# ESP32 register map
Vendor: ESPRESSIF SYSTEMS (SHANGHAI) CO., LTD.; Series: ESP32 Series; File version: 17
CPU: Xtensa LX6 r0p0, little endian, no MPU, FPU, 0 interrupt priority bits
Address unit: 32 bits
Registers are 32-bit, read-write, reset 0x0 unless marked. A register's access mark holds for its fields unless they carry their own. Offsets are from the block's base; [hi:lo] are bit positions; {n}, {i} and the like mark numbered series.

## LEDC — LED Control PWM (Pulse Width Modulation)
Base 0x3FF59000
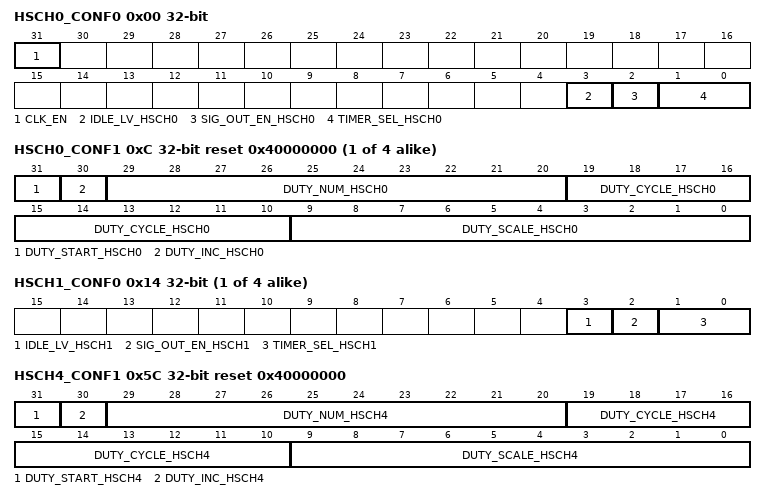
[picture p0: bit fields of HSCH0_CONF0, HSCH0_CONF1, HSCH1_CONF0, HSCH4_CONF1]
0x00 HSCH0_CONF0
  [31] CLK_EN — This bit is clock gating control signal. when software config LED_PWM internal registers it controls the register clock.
  [3] IDLE_LV_HSCH0 — This bit is used to control the output value when high speed channel0 is off.
  [2] SIG_OUT_EN_HSCH0 — This is the output enable control bit for high speed channel0
  [1:0] TIMER_SEL_HSCH0 — There are four high speed timers the two bits are used to select one of them for high speed channel0. 2'b00: seletc hstimer0. 2'b01: select hstimer1. 2'b10: select hstimer2. 2'b11: select hstimer3.
{0x4+0x14*i} HSCH{i}_HPOINT (i=0..7)
  [19:0] HPOINT_HSCH{i} — The output value changes to high when htimerx(x=[0 3]) selected by high speed channel{i} has reached reg_hpoint_hsch{i}[19:0]
{0x8+0x14*i} HSCH{i}_DUTY ro (i=0..7)
  [24:0] DUTY_HSCH{i} — This register represents the current duty of the output signal for high speed channel{i}.
{0xC+0x14*i} HSCH{i}_CONF1 reset 0x40000000 (i=0..3)
  [31] DUTY_START_HSCH{i} — When reg_duty_num_hsch{i} reg_duty_cycle_hsch{i} and reg_duty_scale_hsch{i} has been configured. these register won't take effect until set reg_duty_start_hsch{i}. this bit is automatically cleared by hardware.
  [30] DUTY_INC_HSCH{i} — This register is used to increase the duty of output signal or decrease the duty of output signal for high speed channel{i}.
  [29:20] DUTY_NUM_HSCH{i} — This register is used to control the num of increased or decreased times for high speed channel{i}.
  [19:10] DUTY_CYCLE_HSCH{i} — This register is used to increase or decrease the duty every reg_duty_cycle_hsch{i} cycles for high speed channel{i}.
  [9:0] DUTY_SCALE_HSCH{i} — This register controls the increase or decrease step scale for high speed channel{i}.
{0x10+0x14*i} HSCH{i}_DUTY_R access not given (i=0..7)
{0x0+0x14*i} HSCH{i}_CONF0 (i=1..4)
  [3] IDLE_LV_HSCH{i} — This bit is used to control the output value when high speed channel{i} is off.
  [2] SIG_OUT_EN_HSCH{i} — This is the output enable control bit for high speed channel{i}
  [1:0] TIMER_SEL_HSCH{i} — There are four high speed timers the two bits are used to select one of them for high speed channel{i}. 2'b00: seletc hstimer0. 2'b01: select hstimer1. 2'b10: select hstimer2. 2'b11: select hstimer3.
0x5C HSCH4_CONF1 reset 0x40000000
  [31] DUTY_START_HSCH4 — When reg_duty_num_hsch1 reg_duty_cycle_hsch1 and reg_duty_scale_hsch1 has been configured. these register won't take effect until set reg_duty_start_hsch1. this bit is automatically cleared by hardware.
  [30] DUTY_INC_HSCH4 — This register is used to increase the duty of output signal or decrease the duty of output signal for high speed channel4.
  [29:20] DUTY_NUM_HSCH4 — This register is used to control the num of increased or decreased times for high speed channel1.
  [19:10] DUTY_CYCLE_HSCH4 — This register is used to increase or decrease the duty every reg_duty_cycle_hsch4 cycles for high speed channel4.
  [9:0] DUTY_SCALE_HSCH4 — This register controls the increase or decrease step scale for high speed channel4.
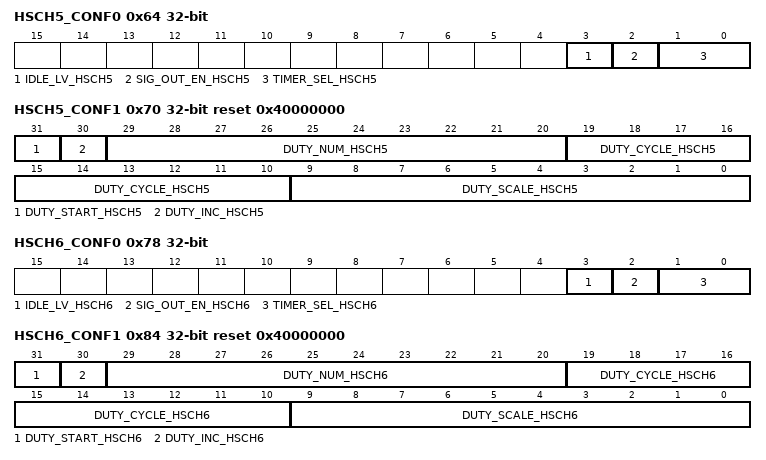
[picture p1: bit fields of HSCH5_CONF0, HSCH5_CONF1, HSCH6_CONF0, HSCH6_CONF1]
0x64 HSCH5_CONF0
  [3] IDLE_LV_HSCH5 — This bit is used to control the output value when high speed channel5 is off.
  [2] SIG_OUT_EN_HSCH5 — This is the output enable control bit for high speed channel5.
  [1:0] TIMER_SEL_HSCH5 — There are four high speed timers the two bits are used to select one of them for high speed channel5. 2'b00: seletc hstimer0. 2'b01: select hstimer1. 2'b10: select hstimer2. 2'b11: select hstimer3.
0x70 HSCH5_CONF1 reset 0x40000000
  [31] DUTY_START_HSCH5 — When reg_duty_num_hsch5 reg_duty_cycle_hsch5 and reg_duty_scale_hsch5 has been configured. these register won't take effect until set reg_duty_start_hsch5. this bit is automatically cleared by hardware.
  [30] DUTY_INC_HSCH5 — This register is used to increase the duty of output signal or decrease the duty of output signal for high speed channel5.
  [29:20] DUTY_NUM_HSCH5 — This register is used to control the num of increased or decreased times for high speed channel5.
  [19:10] DUTY_CYCLE_HSCH5 — This register is used to increase or decrease the duty every reg_duty_cycle_hsch5 cycles for high speed channel5.
  [9:0] DUTY_SCALE_HSCH5 — This register controls the increase or decrease step scale for high speed channel5.
0x78 HSCH6_CONF0
  [3] IDLE_LV_HSCH6 — This bit is used to control the output value when high speed channel6 is off.
  [2] SIG_OUT_EN_HSCH6 — This is the output enable control bit for high speed channel6
  [1:0] TIMER_SEL_HSCH6 — There are four high speed timers the two bits are used to select one of them for high speed channel6. 2'b00: seletc hstimer0. 2'b01: select hstimer1. 2'b10: select hstimer2. 2'b11: select hstimer3.
0x84 HSCH6_CONF1 reset 0x40000000
  [31] DUTY_START_HSCH6 — When reg_duty_num_hsch1 reg_duty_cycle_hsch1 and reg_duty_scale_hsch1 has been configured. these register won't take effect until set reg_duty_start_hsch1. this bit is automatically cleared by hardware.
  [30] DUTY_INC_HSCH6 — This register is used to increase the duty of output signal or decrease the duty of output signal for high speed channel6.
  [29:20] DUTY_NUM_HSCH6 — This register is used to control the num of increased or decreased times for high speed channel6.
  [19:10] DUTY_CYCLE_HSCH6 — This register is used to increase or decrease the duty every reg_duty_cycle_hsch6 cycles for high speed channel6.
  [9:0] DUTY_SCALE_HSCH6 — This register controls the increase or decrease step scale for high speed channel6.
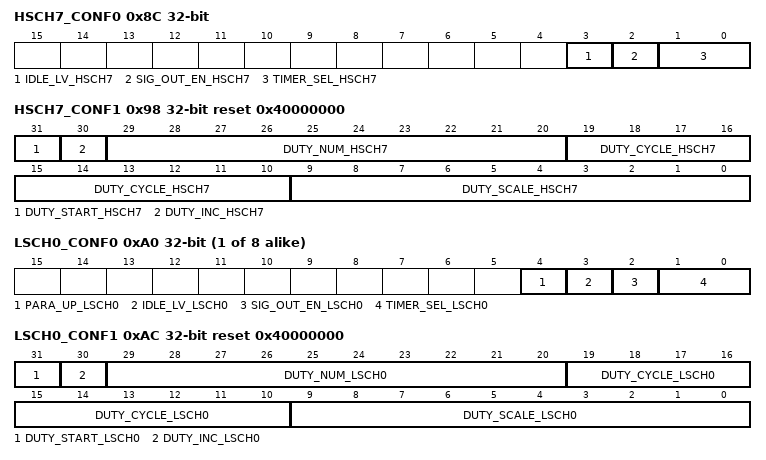
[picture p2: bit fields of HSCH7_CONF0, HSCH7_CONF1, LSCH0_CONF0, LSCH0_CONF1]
0x8C HSCH7_CONF0
  [3] IDLE_LV_HSCH7 — This bit is used to control the output value when high speed channel7 is off.
  [2] SIG_OUT_EN_HSCH7 — This is the output enable control bit for high speed channel7.
  [1:0] TIMER_SEL_HSCH7 — There are four high speed timers the two bits are used to select one of them for high speed channel7. 2'b00: seletc hstimer0. 2'b01: select hstimer1. 2'b10: select hstimer2. 2'b11: select hstimer3.
0x98 HSCH7_CONF1 reset 0x40000000
  [31] DUTY_START_HSCH7 — When reg_duty_num_hsch1 reg_duty_cycle_hsch1 and reg_duty_scale_hsch1 has been configured. these register won't take effect until set reg_duty_start_hsch1. this bit is automatically cleared by hardware.
  [30] DUTY_INC_HSCH7 — This register is used to increase the duty of output signal or decrease the duty of output signal for high speed channel6.
  [29:20] DUTY_NUM_HSCH7 — This register is used to control the num of increased or decreased times for high speed channel6.
  [19:10] DUTY_CYCLE_HSCH7 — This register is used to increase or decrease the duty every reg_duty_cycle_hsch7 cycles for high speed channel7.
  [9:0] DUTY_SCALE_HSCH7 — This register controls the increase or decrease step scale for high speed channel7.
{0xA0+0x14*i} LSCH{i}_CONF0 (i=0..7)
  [4] PARA_UP_LSCH{i} — This bit is used to update register LEDC_LSCH{i}_HPOINT and LEDC_LSCH{i}_DUTY for low speed channel{i}.
  [3] IDLE_LV_LSCH{i} — This bit is used to control the output value when low speed channel{i} is off.
  [2] SIG_OUT_EN_LSCH{i} — This is the output enable control bit for low speed channel{i}.
  [1:0] TIMER_SEL_LSCH{i} — There are four low speed timers the two bits are used to select one of them for low speed channel{i}. 2'b00: seletc lstimer0. 2'b01: select lstimer1. 2'b10: select lstimer2. 2'b11: select lstimer3.
{0xA4+0x14*i} LSCH{i}_HPOINT (i=0..7)
  [19:0] HPOINT_LSCH{i} — The output value changes to high when lstimerx(x=[0 3]) selected by low speed channel{i} has reached reg_hpoint_lsch{i}[19:0]
{0xA8+0x14*i} LSCH{i}_DUTY ro (i=0..7)
  [24:0] DUTY_LSCH{i} — This register represents the current duty of the output signal for low speed channel{i}.
0xAC LSCH0_CONF1 reset 0x40000000
  [31] DUTY_START_LSCH0 — When reg_duty_num_hsch1 reg_duty_cycle_hsch1 and reg_duty_scale_hsch1 has been configured. these register won't take effect until set reg_duty_start_hsch1. this bit is automatically cleared by hardware.
  [30] DUTY_INC_LSCH0 — This register is used to increase the duty of output signal or decrease the duty of output signal for low speed channel6.
  [29:20] DUTY_NUM_LSCH0 — This register is used to control the num of increased or decreased times for low speed channel6.
  [19:10] DUTY_CYCLE_LSCH0 — This register is used to increase or decrease the duty every reg_duty_cycle_lsch0 cycles for low speed channel0.
  [9:0] DUTY_SCALE_LSCH0 — This register controls the increase or decrease step scale for low speed channel0.
{0xB0+0x14*i} LSCH{i}_DUTY_R access not given (i=0..7)
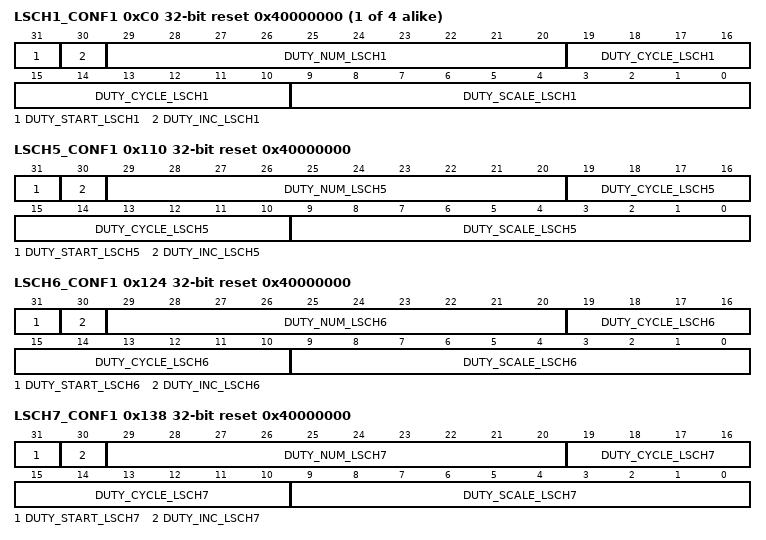
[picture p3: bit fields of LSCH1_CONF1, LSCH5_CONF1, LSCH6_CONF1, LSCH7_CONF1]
{0xAC+0x14*i} LSCH{i}_CONF1 reset 0x40000000 (i=1..4)
  [31] DUTY_START_LSCH{i} — When reg_duty_num_hsch{i} reg_duty_cycle_hsch{i} and reg_duty_scale_hsch{i} has been configured. these register won't take effect until set reg_duty_start_hsch{i}. this bit is automatically cleared by hardware.
  [30] DUTY_INC_LSCH{i} — This register is used to increase the duty of output signal or decrease the duty of output signal for low speed channel{i}.
  [29:20] DUTY_NUM_LSCH{i} — This register is used to control the num of increased or decreased times for low speed channel{i}.
  [19:10] DUTY_CYCLE_LSCH{i} — This register is used to increase or decrease the duty every reg_duty_cycle_lsch{i} cycles for low speed channel{i}.
  [9:0] DUTY_SCALE_LSCH{i} — This register controls the increase or decrease step scale for low speed channel{i}.
0x110 LSCH5_CONF1 reset 0x40000000
  [31] DUTY_START_LSCH5 — When reg_duty_num_hsch4 reg_duty_cycle_hsch4 and reg_duty_scale_hsch4 has been configured. these register won't take effect until set reg_duty_start_hsch4. this bit is automatically cleared by hardware.
  [30] DUTY_INC_LSCH5 — This register is used to increase the duty of output signal or decrease the duty of output signal for low speed channel5.
  [29:20] DUTY_NUM_LSCH5 — This register is used to control the num of increased or decreased times for low speed channel5.
  [19:10] DUTY_CYCLE_LSCH5 — This register is used to increase or decrease the duty every reg_duty_cycle_lsch5 cycles for low speed channel4.
  [9:0] DUTY_SCALE_LSCH5 — This register controls the increase or decrease step scale for low speed channel5.
0x124 LSCH6_CONF1 reset 0x40000000
  [31] DUTY_START_LSCH6 — When reg_duty_num_hsch6 reg_duty_cycle_hsch6 and reg_duty_scale_hsch6 has been configured. these register won't take effect until set reg_duty_start_hsch6. this bit is automatically cleared by hardware.
  [30] DUTY_INC_LSCH6 — This register is used to increase the duty of output signal or decrease the duty of output signal for low speed channel6.
  [29:20] DUTY_NUM_LSCH6 — This register is used to control the num of increased or decreased times for low speed channel6.
  [19:10] DUTY_CYCLE_LSCH6 — This register is used to increase or decrease the duty every reg_duty_cycle_lsch6 cycles for low speed channel6.
  [9:0] DUTY_SCALE_LSCH6 — This register controls the increase or decrease step scale for low speed channel6.
0x138 LSCH7_CONF1 reset 0x40000000
  [31] DUTY_START_LSCH7 — When reg_duty_num_hsch4 reg_duty_cycle_hsch4 and reg_duty_scale_hsch4 has been configured. these register won't take effect until set reg_duty_start_hsch4. this bit is automatically cleared by hardware.
  [30] DUTY_INC_LSCH7 — This register is used to increase the duty of output signal or decrease the duty of output signal for low speed channel4.
  [29:20] DUTY_NUM_LSCH7 — This register is used to control the num of increased or decreased times for low speed channel4.
  [19:10] DUTY_CYCLE_LSCH7 — This register is used to increase or decrease the duty every reg_duty_cycle_lsch7 cycles for low speed channel7.
  [9:0] DUTY_SCALE_LSCH7 — This register controls the increase or decrease step scale for low speed channel7.
0x140 HSTIMER0_CONF reset 0x1000000
  [35:31] HSTIMER0_LIM
  [25] TICK_SEL_HSTIMER0 — This bit is used to choose apb_clk or ref_tick for high speed timer0. 1'b1:apb_clk 0:ref_tick
  [24] HSTIMER0_RST — This bit is used to reset high speed timer0 the counter will be 0 after reset.
  [23] HSTIMER0_PAUSE — This bit is used to pause the counter in high speed timer0
  [22:5] DIV_NUM_HSTIMER0 — This register is used to configure parameter for divider in high speed timer0 the least significant eight bits represent the decimal part.
  [4:0] HSTIMER0_DUTY_RES — This register controls the range of the counter in high speed timer0. the counter range is [0 2**reg_hstimer0_lim] the max bit width for counter is 20.
0x144 HSTIMER0_VALUE ro
  [19:0] HSTIMER0_CNT — software can read this register to get the current counter value in high speed timer0
0x148 HSTIMER1_CONF reset 0x1000000
  [35:31] HSTIMER1_LIM
  [25] TICK_SEL_HSTIMER1 — This bit is used to choose apb_clk or ref_tick for high speed timer1. 1'b1:apb_clk 0:ref_tick
  [24] HSTIMER1_RST — This bit is used to reset high speed timer1 the counter will be 0 after reset.
  [23] HSTIMER1_PAUSE — This bit is used to pause the counter in high speed timer1
  [22:5] DIV_NUM_HSTIMER1 — This register is used to configure parameter for divider in high speed timer1 the least significant eight bits represent the decimal part.
  [4:0] HSTIMER1_DUTY_RES — This register controls the range of the counter in high speed timer1. the counter range is [0 2**reg_hstimer1_lim] the max bit width for counter is 20.
0x14C HSTIMER1_VALUE ro
  [19:0] HSTIMER1_CNT — software can read this register to get the current counter value in high speed timer1.
0x150 HSTIMER2_CONF reset 0x1000000
  [35:31] HSTIMER2_LIM
  [25] TICK_SEL_HSTIMER2 — This bit is used to choose apb_clk or ref_tick for high speed timer2. 1'b1:apb_clk 0:ref_tick
  [24] HSTIMER2_RST — This bit is used to reset high speed timer2 the counter will be 0 after reset.
  [23] HSTIMER2_PAUSE — This bit is used to pause the counter in high speed timer2
  [22:5] DIV_NUM_HSTIMER2 — This register is used to configure parameter for divider in high speed timer2 the least significant eight bits represent the decimal part.
  [4:0] HSTIMER2_DUTY_RES — This register controls the range of the counter in high speed timer2. the counter range is [0 2**reg_hstimer2_lim] the max bit width for counter is 20.
0x154 HSTIMER2_VALUE ro
  [19:0] HSTIMER2_CNT — software can read this register to get the current counter value in high speed timer2
0x158 HSTIMER3_CONF reset 0x1000000
  [35:31] HSTIMER3_LIM
  [25] TICK_SEL_HSTIMER3 — This bit is used to choose apb_clk or ref_tick for high speed timer3. 1'b1:apb_clk 0:ref_tick
  [24] HSTIMER3_RST — This bit is used to reset high speed timer3 the counter will be 0 after reset.
  [23] HSTIMER3_PAUSE — This bit is used to pause the counter in high speed timer3
  [22:5] DIV_NUM_HSTIMER3 — This register is used to configure parameter for divider in high speed timer3 the least significant eight bits represent the decimal part.
  [4:0] HSTIMER3_DUTY_RES — This register controls the range of the counter in high speed timer3. the counter range is [0 2**reg_hstimer3_lim] the max bit width for counter is 20.
0x15C HSTIMER3_VALUE ro
  [19:0] HSTIMER3_CNT — software can read this register to get the current counter value in high speed timer3
0x160 LSTIMER0_CONF reset 0x1000000
  [35:31] LSTIMER0_LIM
  [26] LSTIMER0_PARA_UP — Set this bit to update reg_div_num_lstime0 and reg_lstimer0_lim.
  [25] TICK_SEL_LSTIMER0 — This bit is used to choose slow_clk or ref_tick for low speed timer0. 1'b1:slow_clk 0:ref_tick
  [24] LSTIMER0_RST — This bit is used to reset low speed timer0 the counter will be 0 after reset.
  [23] LSTIMER0_PAUSE — This bit is used to pause the counter in low speed timer0.
  [22:5] DIV_NUM_LSTIMER0 — This register is used to configure parameter for divider in low speed timer0 the least significant eight bits represent the decimal part.
  [4:0] LSTIMER0_DUTY_RES — This register controls the range of the counter in low speed timer0. the counter range is [0 2**reg_lstimer0_lim] the max bit width for counter is 20.
{0x164+8i} LSTIMER{i}_VALUE ro (i=0..3)
  [19:0] LSTIMER{i}_CNT — software can read this register to get the current counter value in low speed timer{i}.
0x168 LSTIMER1_CONF reset 0x1000000
  [35:31] LSTIMER1_LIM
  [26] LSTIMER1_PARA_UP — Set this bit to update reg_div_num_lstime1 and reg_lstimer1_lim.
  [25] TICK_SEL_LSTIMER1 — This bit is used to choose slow_clk or ref_tick for low speed timer1. 1'b1:slow_clk 0:ref_tick
  [24] LSTIMER1_RST — This bit is used to reset low speed timer1 the counter will be 0 after reset.
  [23] LSTIMER1_PAUSE — This bit is used to pause the counter in low speed timer1.
  [22:5] DIV_NUM_LSTIMER1 — This register is used to configure parameter for divider in low speed timer1 the least significant eight bits represent the decimal part.
  [4:0] LSTIMER1_DUTY_RES — This register controls the range of the counter in low speed timer1. the counter range is [0 2**reg_lstimer1_lim] the max bit width for counter is 20.
0x170 LSTIMER2_CONF reset 0x1000000
  [35:31] LSTIMER2_LIM
  [26] LSTIMER2_PARA_UP — Set this bit to update reg_div_num_lstime2 and reg_lstimer2_lim.
  [25] TICK_SEL_LSTIMER2 — This bit is used to choose slow_clk or ref_tick for low speed timer2. 1'b1:slow_clk 0:ref_tick
  [24] LSTIMER2_RST — This bit is used to reset low speed timer2 the counter will be 0 after reset.
  [23] LSTIMER2_PAUSE — This bit is used to pause the counter in low speed timer2.
  [22:5] DIV_NUM_LSTIMER2 — This register is used to configure parameter for divider in low speed timer2 the least significant eight bits represent the decimal part.
  [4:0] LSTIMER2_DUTY_RES — This register controls the range of the counter in low speed timer2. the counter range is [0 2**reg_lstimer2_lim] the max bit width for counter is 20.
0x178 LSTIMER3_CONF reset 0x1000000
  [35:31] LSTIMER3_LIM
  [26] LSTIMER3_PARA_UP — Set this bit to update reg_div_num_lstime3 and reg_lstimer3_lim.
  [25] TICK_SEL_LSTIMER3 — This bit is used to choose slow_clk or ref_tick for low speed timer3. 1'b1:slow_clk 0:ref_tick
  [24] LSTIMER3_RST — This bit is used to reset low speed timer3 the counter will be 0 after reset.
  [23] LSTIMER3_PAUSE — This bit is used to pause the counter in low speed timer3.
  [22:5] DIV_NUM_LSTIMER3 — This register is used to configure parameter for divider in low speed timer3 the least significant eight bits represent the decimal part.
  [4:0] LSTIMER3_DUTY_RES — This register controls the range of the counter in low speed timer3. the counter range is [0 2**reg_lstimer3_lim] the max bit width for counter is 20.
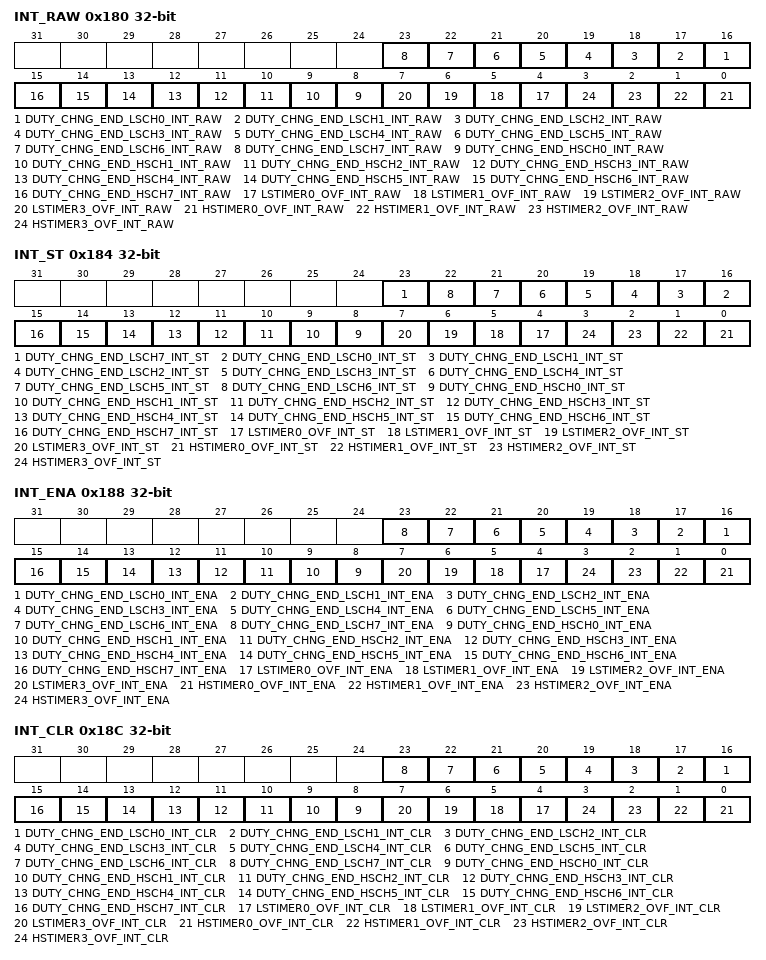
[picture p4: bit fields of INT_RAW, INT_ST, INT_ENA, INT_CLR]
0x180 INT_RAW ro
  [n+16] DUTY_CHNG_END_LSCH{n}_INT_RAW (n=0..7) — The interrupt raw bit for low speed channel {n} duty change done.
  [n+8] DUTY_CHNG_END_HSCH{n}_INT_RAW (n=0..7) — The interrupt raw bit for high speed channel {n} duty change done.
  [n+4] LSTIMER{n}_OVF_INT_RAW (n=0..3) — The interrupt raw bit for low speed channel{n} counter overflow.
  [n] HSTIMER{n}_OVF_INT_RAW (n=0..3) — The interrupt raw bit for high speed channel{n} counter overflow.
0x184 INT_ST ro
  [23] DUTY_CHNG_END_LSCH7_INT_ST — The interrupt status bit for low speed channel 7 duty change done event
  [n+16] DUTY_CHNG_END_LSCH{n}_INT_ST (n=0..6) — The interrupt status bit for low speed channel {n} duty change done event.
  [n+8] DUTY_CHNG_END_HSCH{n}_INT_ST (n=0..7) — The interrupt status bit for high speed channel {n} duty change done event.
  [n+4] LSTIMER{n}_OVF_INT_ST (n=0..3) — The interrupt status bit for low speed channel{n} counter overflow event.
  [n] HSTIMER{n}_OVF_INT_ST (n=0..3) — The interrupt status bit for high speed channel{n} counter overflow event.
0x188 INT_ENA
  [n+16] DUTY_CHNG_END_LSCH{n}_INT_ENA (n=0..7) — The interrupt enable bit for low speed channel {n} duty change done interrupt.
  [n+8] DUTY_CHNG_END_HSCH{n}_INT_ENA (n=0..7) — The interrupt enable bit for high speed channel {n} duty change done interrupt.
  [n+4] LSTIMER{n}_OVF_INT_ENA (n=0..3) — The interrupt enable bit for low speed channel{n} counter overflow interrupt.
  [n] HSTIMER{n}_OVF_INT_ENA (n=0..3) — The interrupt enable bit for high speed channel{n} counter overflow interrupt.
0x18C INT_CLR wo
  [n+16] DUTY_CHNG_END_LSCH{n}_INT_CLR (n=0..7) — Set this bit to clear low speed channel {n} duty change done interrupt.
  [n+8] DUTY_CHNG_END_HSCH{n}_INT_CLR (n=0..7) — Set this bit to clear high speed channel {n} duty change done interrupt.
  [n+4] LSTIMER{n}_OVF_INT_CLR (n=0..3) — Set this bit to clear low speed channel{n} counter overflow interrupt.
  [n] HSTIMER{n}_OVF_INT_CLR (n=0..3) — Set this bit to clear high speed channel{n} counter overflow interrupt.
0x190 CONF
  [0] APB_CLK_SEL — This bit is used to set the frequency of slow_clk. 1'b1:80mhz 1'b0:8mhz
0x1FC DATE reset 0x16031700
  [31:0] DATE — This register represents the version .
